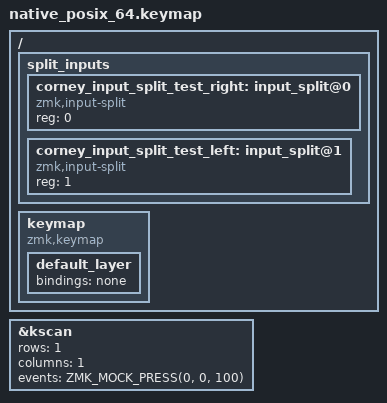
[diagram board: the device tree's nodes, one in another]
#include <behaviors.dtsi>
#include <dt-bindings/zmk/keys.h>
#include <dt-bindings/zmk/kscan_mock.h>

/ {
    split_inputs {
        #address-cells = <1>;
        #size-cells = <0>;

        corney_input_split_test_right: input_split@0 {
            compatible = "zmk,input-split";
            reg = <0>;
        };

        corney_input_split_test_left: input_split@1 {
            compatible = "zmk,input-split";
            reg = <1>;
        };
    };

    keymap {
        compatible = "zmk,keymap";

        default_layer {
            bindings = <&none>;
        };
    };
};

&kscan {
    rows = <1>;
    columns = <1>;
    events = <ZMK_MOCK_PRESS(0, 0, 100)>;
};
